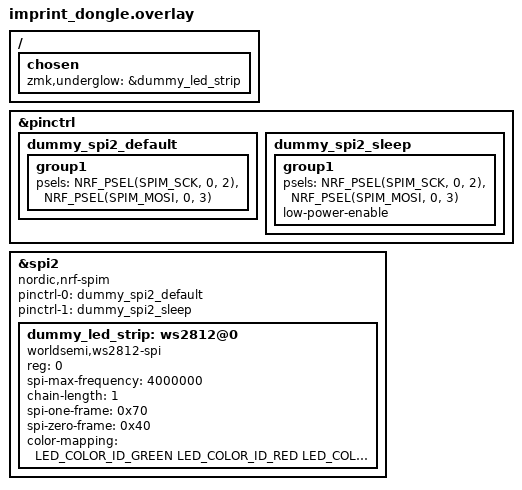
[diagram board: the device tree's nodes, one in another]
#include <dt-bindings/led/led.h>

&pinctrl {
    dummy_spi2_default: dummy_spi2_default {
        group1 {
            psels = <NRF_PSEL(SPIM_SCK, 0, 2)>,
                <NRF_PSEL(SPIM_MOSI, 0, 3)>;
        };
    };

    dummy_spi2_sleep: dummy_spi2_sleep {
        group1 {
            psels = <NRF_PSEL(SPIM_SCK, 0, 2)>,
                <NRF_PSEL(SPIM_MOSI, 0, 3)>;
            low-power-enable;
        };
    };
};

&spi2 {
    status = "okay";
    compatible = "nordic,nrf-spim";
    pinctrl-0 = <&dummy_spi2_default>;
    pinctrl-1 = <&dummy_spi2_sleep>;
    pinctrl-names = "default", "sleep";

    dummy_led_strip: ws2812@0 {
        compatible = "worldsemi,ws2812-spi";
        reg = <0>;
        spi-max-frequency = <4000000>;
        chain-length = <1>;
        spi-one-frame = <0x70>;
        spi-zero-frame = <0x40>;
        color-mapping = <LED_COLOR_ID_GREEN LED_COLOR_ID_RED LED_COLOR_ID_BLUE>;
    };
};

/ {
    chosen {
        zmk,underglow = &dummy_led_strip;
    };
};
